# Sis08dC2Membrane register map
File version: 1.0
SOS-09-B generated CMSIS-SVD description for Sis08dC2Membrane
Registers are 32-bit, read-only, reset 0x0 unless marked. A register's access mark holds for its fields unless they carry their own. Offsets are from the block's base; lines under a group give offsets from that group; [hi:lo] are bit positions; {n}, {i} and the like mark numbered series; 'fields as' and 'values as' point back to an identical list; <NAME> marks a mode.

## Memory map
0x40010000 Sis08dC2Membrane size 0x14 — SOS-09-B channel block for Sis08dC2Membrane

## Interrupts
0 membrane_irq (Sis08dC2Membrane) — SOS-09-B placeholder vector for channel 'membrane_status'
1 transfer_irq (Sis08dC2Membrane) — SOS-09-B placeholder vector for channel 'transfer_mailbox_notify'

## Sis08dC2Membrane — SOS-09-B channel block for Sis08dC2Membrane
Base 0x40010000
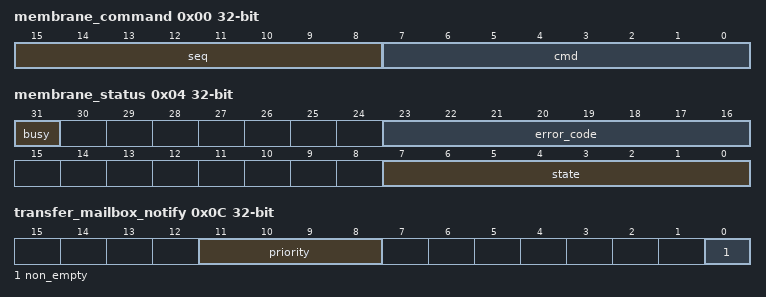
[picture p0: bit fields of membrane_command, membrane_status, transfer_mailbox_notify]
0x00 membrane_command wo — SOS-09-B channel 'membrane_command' (kind=command, dir=sw→hw)
  [15:8] seq — bit-field 'seq' (access=WO)
  [7:0] cmd — bit-field 'cmd' (access=WO)
0x04 membrane_status read-clears — SOS-09-B channel 'membrane_status' (kind=status, dir=hw→sw)
  [31] busy — bit-field 'busy' (access=RO)
  [23:16] error_code read-clears — bit-field 'error_code' (access=RO)
  [7:0] state — bit-field 'state' (access=RO)
0x08 transfer_mailbox_data rw — SOS-09-B channel 'transfer_mailbox_data' (kind=queue, dir=hw↔sw)
0x0C transfer_mailbox_notify read-clears — SOS-09-B channel 'transfer_mailbox_notify' (kind=status, dir=hw→sw)
  [11:8] priority — bit-field 'priority' (access=RO)
  [0] non_empty read-clears — bit-field 'non_empty' (access=RO)
0x10 sram_window rw — SOS-09-B channel 'sram_window' (kind=shared, dir=hw↔sw)
